# LPC18xx register map
File version: 18
Registers are 32-bit, read-write, reset 0x0 unless marked. A register's access mark holds for its fields unless they carry their own. Offsets are from the block's base; [hi:lo] are bit positions.

## ETHERNET — Product name title=UM10430 Chapter title=LPC18xx Ethernet Modification date=1/20/2011 Major revision=0 Minor revision=7
Base 0x40010000
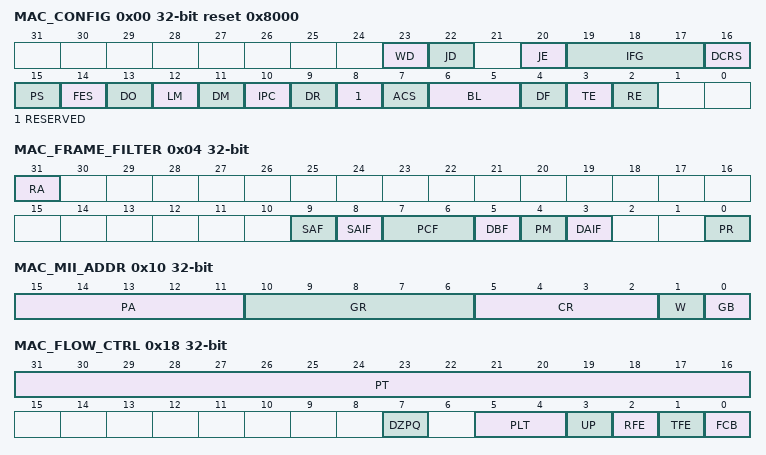
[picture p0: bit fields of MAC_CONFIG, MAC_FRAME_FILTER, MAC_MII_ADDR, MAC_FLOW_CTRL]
0x00 MAC_CONFIG reset 0x8000 — MAC configuration register
  [23] WD — Watchdog Disable When this bit is set, the MAC disables the watchdog timer on the receiver, and can receive frames of up to 16,384 bytes. When this bit is reset, the MAC allows no more than 2,048 bytes (10,240 if JE is set high) of the frame being received and cuts off any bytes received after that.
  [22] JD — Jabber Disable When this bit is set, the MAC disables the jabber timer on the transmitter, and can transfer frames of up to 16,384 bytes. When this bit is reset, the MAC cuts off the transmitter if the application sends out more than 2,048 bytes of data (10,240 if JE is set high) during transmission.
  [20] JE — Jumbo Frame Enable When this bit is set, MAC allows Jumbo frames of 9,018 bytes (9,022 bytes for VLAN tagged frames) without reporting a giant frame error in the receive frame status.
  [19:17] IFG — Inter-frame gap These bits control the minimum IFG between frames during transmission. 000 = 96 bit times 001 = 88 bit times 010 = 80 bit times ... 000 = 40 bit times Note that in Half-Duplex mode, the minimum IFG can be configured for 64 bit times (IFG = 100) only. Lower values are not considered
  [16] DCRS — Disable carrier sense during transmission When set high, this bit makes the MAC transmitter ignore the (G)MII CRS signal during frame transmission in Half-Duplex mode. This request results in no errors generated due to Loss of Carrier or No Carrier during such transmission. When this bit is low, the MAC transmitter generates such errors due to Carrier Sense and will even abort the transmissions.
  [15] PS — Port select 1 = MII (100 Mbp) - this is the only allowed value.
  [14] FES — Speed Indicates the speed in Fast Ethernet (MII) mode: 0 = 10 Mbps 1 = 100 Mbps .
  [13] DO — Disable Receive Own When this bit is set, the MAC disables the reception of frames in Half-Duplex mode. When this bit is reset, the MAC receives all packets that are given by the PHY while transmitting. This bit is not applicable if the MAC is operating in Full-Duplex mode.
  [12] LM — Loopback Mode When this bit is set, the MAC operates in loopback mode at MII. The (G)MII Receive clock input is required for the loopback to work properly, as the Transmit clock is not looped-back internally.
  [11] DM — Duplex Mode When this bit is set, the MAC operates in a Full-Duplex mode where it can transmit and receive simultaneously.
  [10] IPC — Checksum Offload When this bit is set, the MAC calculates the 16-bit one's complement of the one's complement sum of all received Ethernet frame payloads. It also checks whether the IPv4 Header checksum (assumed to be bytes 25-26 or 29-30 (VLAN-tagged) of the received Ethernet frame) is correct for the received frame and gives the status in the receive status word. The MAC core also appends the 16-bit checksum calculated for the IP header datagram payload (bytes after the IPv4 header) and appends it to the Ethernet frame transferred to the application (when Type 2 COE is deselected). When this bit is reset, this function is disabled. When Type 2 COE is selected, this bit, when set, enables IPv4 checksum checking for received frame payload's TCP/UDP/ICMP headers. When this bit is reset, the COE function in the receiver is disabled and the corresponding PCE and IP HCE status bits (see ) are always cleared.
  [9] DR — Disable Retry When this bit is set, the MAC will attempt only 1 transmission. When a collision occurs on the MII, the MAC will ignore the current frame transmission and report a Frame Abort with excessive collision error in the transmit frame status. When this bit is reset, the MAC will attempt retries based on the settings of BL. This bit is applicable only to Half-Duplex mode and is reserved (RO with default value) in Full- Duplex-only configuration.
  [8] RESERVED — Link Up/Down Indicates whether the link is up or down during the transmission of configuration in SMII interface: 0 = Link down 1 = Link up
  [7] ACS — Automatic Pad/CRC Stripping When this bit is set, the MAC strips the Pad/FCS field on incoming frames only if the length's field value is less than or equal to 1,500 bytes. All received frames with length field greater than or equal to 1,501 bytes are passed to the application without stripping the Pad/FCS field. When this bit is reset, the MAC will pass all incoming frames to the Host unmodified.
  [6:5] BL — Back-Off Limit The Back-Off limit determines the random integer number (r) of slot time delays (4,096 bit times for 1000 Mbps and 512 bit times for 10/100 Mbps) the MAC waits before rescheduling a transmission attempt during retries after a collision. This bit is applicable only to Half-Duplex mode and is reserved (RO) in Full-Duplex-only configuration. 00: k = min (n, 10) 01: k = min (n, 8) 10: k = min (n, 4) 11: k = min (n, 1) where n = retransmission attempt. The random integer r takes the value in the range between 0 and 2^k.
  [4] DF — Deferral Check When this bit is set, the deferral check function is enabled in the MAC. The MAC will issue a Frame Abort status, along with the excessive deferral error bit set in the transmit frame status when the transmit state machine is deferred for more than 24,288 bit times in 10/100-Mbps mode. If the Core is configured for 1000 Mbps operation, or if the Jumbo frame mode is enabled in 10/100-Mbps mode, the threshold for deferral is 155,680 bits times. Deferral begins when the transmitter is ready to transmit, but is prevented because of an active CRS (carrier sense) signal on the MII. Defer time is not cumulative. If the transmitter defers for 10,000 bit times, then transmits, collides, backs off, and then has to defer again after completion of back-off, the deferral timer resets to 0 and restarts. When this bit is reset, the deferral check function is disabled and the MAC defers until the CRS signal goes inactive. This bit is applicable only in Half-Duplex mode and is reserved (RO) in Full-Duplex-only configuration.
  [3] TE — Transmitter Enable When this bit is set, the transmit state machine of the MAC is enabled for transmission on the MII. When this bit is reset, the MAC transmit state machine is disabled after the completion of the transmission of the current frame, and will not transmit any further frames.
  [2] RE — Receiver enable When this bit is set, the receiver state machine of the MAC is enabled for receiving frames from the MII. When this bit is reset, the MAC receive state machine is disabled after the completion of the reception of the current frame, and will not receive any further frames from the MII.
0x04 MAC_FRAME_FILTER
  [31] RA — Receive all When this bit is set, the MAC Receiver module passes to the Application all frames received irrespective of whether they pass the address filter. The result of the SA/DA filtering is updated (pass or fail) in the corresponding bits in the Receive Status Word. When this bit is reset, the Receiver module passes to the Application only those frames that pass the SA/DA address filter.
  [9] SAF — Source Address Filter Enable The MAC core compares the SA field of the received frames with the values programmed in the enabled SA registers. If the comparison matches, then the SAMatch bit of RxStatus Word is set high. When this bit is set high and the SA filter fails, the MAC drops the frame. When this bit is reset, then the MAC Core forwards the received frame to the application and with the updated SA Match bit of the RxStatus depending on the SA address comparison.
  [8] SAIF — SA Inverse Filtering When this bit is set, the Address Check block operates in inverse filtering mode for the SA address comparison. The frames whose SA matches the SA registers will be marked as failing the SA Address filter. When this bit is reset, frames whose SA does not match the SA registers will be marked as failing the SA Address filter.
  [7:6] PCF — Pass Control Frames These bits control the forwarding of all control frames (including unicast and multicast PAUSE frames). Note that the processing of PAUSE control frames depends only on RFE of Flow Control Register[2]. 00 = MAC filters all control frames from reaching the application. 01 = MAC forwards all control frames except PAUSE control frames to application even if they fail the Address filter. 10 = MAC forwards all control frames to application even if they fail the Address Filter. 11 = MAC forwards control frames that pass the Address Filter.
  [5] DBF — Disable Broadcast Frames When this bit is set, the AFM module filters all incoming broadcast frames. When this bit is reset, the AFM module passes all received broadcast frames.
  [4] PM — Pass All Multicast When set, this bit indicates that all received frames with a multicast destination address (first bit in the destination address field is '1') are passed. When reset, filtering of multicast frame depends on HMC bit.
  [3] DAIF — DA Inverse Filtering When this bit is set, the Address Check block operates in inverse filtering mode for the DA address comparison for both unicast and multicast frames. When reset, normal filtering of frames is performed.
  [0] PR — Promiscuous Mode When this bit is set, the Address Filter module passes all incoming frames regardless of its destination or source address. The SA/DA Filter Fails status bits of the Receive Status Word will always be cleared when PR is set.
0x08 MAC_HASHTABLE_HIGH — Hash table high register
  [31:0] HTH — Hash table high This field contains the upper 32 bits of Hash table.
0x0C MAC_HASHTABLE_LOW — Hash table low register
  [31:0] HTL — Hash table low This field contains the upper 32 bits of Hash table.
0x10 MAC_MII_ADDR — MII address register
  [15:11] PA — Physical layer address This field tells which of the 32 possible PHY devices are being accessed.
  [10:6] GR — MII register These bits select the desired MII register in the selected PHY device.
  [5:2] CR — CSR clock range The CSR Clock Range selection determines the frequency of the MDC clock . The suggested range of clk_csr_i frequency applicable for each value below (when Bit[5] = 0) ensures that the MDC clock is approximately between the frequency range 1.0 MHz - 2.5 MHz. When bit 5 is set, you can achieve MDC clock of frequency higher than the IEEE 802.3 specified frequency limit of 2.5 MHz and program a clock divider of lower value. For example, when clk_csr_i is of frequency 100 Mhz and you program these bits as 1010, then the resultant MDC clock will be of 12.5 Mhz which is outside the limit of IEEE 802.3 specified range. Please program the values given below only if the interfacing chips supports faster MDC clocks. See Table 320 for bit values.
  [1] W — MII write When set, this bit tells the PHY that this will be a Write operation using the MII Data register. If this bit is not set, this will be a Read operation, placing the data in the MII Data register.
  [0] GB — MII busy This bit should read a logic 0 before writing to this register and the MAC_MII_DATA register. This bit must also be set to 0 during a Write to this register. During a PHY register access, this bit will be set to 1 by the Application to indicate that a Read or Write access is in progress. The MAC_MII_DATA register should be kept valid until this bit is cleared by the MAC during a PHY Write operation. The MAC_MII_DATA register is invalid until this bit is cleared by the MAC during a PHY Read operation. This register should not be written to until this bit is cleared.
0x14 MAC_MII_DATA — MII data register
  [15:0] GD — MII data This contains the 16-bit data value read from the PHY after a Management Read operation or the 16-bit data value to be written to the PHY before a Management Write operation.
0x18 MAC_FLOW_CTRL — Flow control register
  [31:16] PT — Pause time This field holds the value to be used in the Pause Time field in the transmit control frame. If the Pause Time bits is configured to be double-synchronized to the (G)MII clock domain, then consecutive writes to this register should be performed only after at least 4 clock cycles in the destination clock domain.
  [7] DZPQ — Disable Zero-Quanta Pause When set, this bit disables the automatic generation of Zero-Quanta Pause Control frames on the deassertion of the flow-control signal from the FIFO layer . When this bit is reset, normal operation with automatic Zero-Quanta Pause Control frame generation is enabled.
  [5:4] PLT — Pause Low Threshold This field configures the threshold of the PAUSE timer at which the input flow control is checked for automatic retransmission of PAUSE Frame. The threshold values should be always less than the Pause Time configured in Bits[31:16]. For example, if PT = Ox100 (256 slot-times), and PLT = 01, then a second PAUSE frame is automatically transmitted if the flow control signal is asserted at 228 (256 - 28) slot-times after the first PAUSE frame is transmitted.
  [3] UP — Unicast Pause Frame Detect When this bit is set, the MAC will detect the Pause frames with the station's unicast address specified in MAC Address0 High Register and MAC Address0 Low Register, in addition to the detecting Pause frames with the unique multicast address. When this bit is reset, the MAC will detect only a Pause frame with the unique multicast address specified in the 802.3x standard.
  [2] RFE — Receive Flow Control Enable When this bit is set, the MAC will decode the received Pause frame and disable its transmitter for a specified (Pause Time) time. When this bit is reset, the decode function of the Pause frame is disabled.
  [1] TFE — Transmit Flow Control Enable In Full-Duplex mode, when this bit is set, the MAC enables the flow control operation to transmit Pause frames. When this bit is reset, the flow control operation in the MAC is disabled, and the MAC will not transmit any Pause frames. In Half-Duplex mode, when this bit is set, the MAC enables the back-pressure operation. When this bit is reset, the backpressure feature is disabled.
  [0] FCB — Flow Control Busy/Backpressure Activate This bit initiates a Pause Control frame in Full-Duplex mode. In Full-Duplex mode, this bit should be read as 0 before writing to the Flow Control register. To initiate a Pause control frame, the Application must set this bit to 1. During a transfer of the Control Frame, this bit will continue to be set to signify that a frame transmission is in progress. After the completion of Pause control frame transmission, the MAC will reset this bit to 0. The Flow Control register should not be written to until this bit is cleared. In Half-Duplex mode, when this bit is set (and TFE is set), then backpressure is asserted by the MAC Core. During backpressure, when the MAC receives a new frame, the transmitter starts sending a JAM pattern resulting in a collision. This control register bit is logically OR'ed with the mti_flowctrl_i input signal for the backpressure function. When the MAC is configured to Full- Duplex mode, the BPA is automatically disabled.
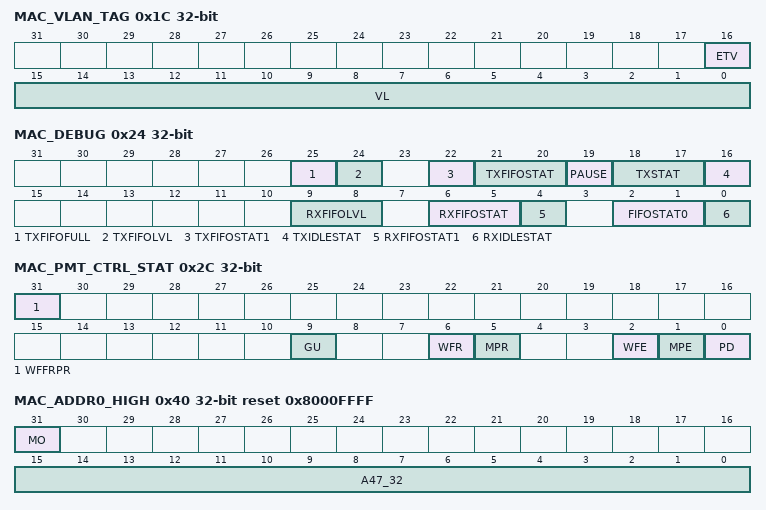
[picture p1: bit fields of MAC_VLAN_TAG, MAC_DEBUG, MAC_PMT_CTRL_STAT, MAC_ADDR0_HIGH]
0x1C MAC_VLAN_TAG — VLAN tag register
  [16] ETV — Enable 12-Bit VLAN Tag Comparison When this bit is set, a 12-bit VLAN identifier, rather than the complete 16-bit VLAN tag, is used for comparison and filtering. Bits[11:0] of the VLAN tag are compared with the corresponding field in the received VLAN-tagged frame. When this bit is reset, all 16 bits of the received VLAN frame's fifteenth and sixteenth bytes are used for comparison.
  [15:0] VL — VLAN Tag Identifier for Receive Frames This contains the 802.1Q VLAN tag to identify VLAN frames, and is compared to the fifteenth and sixteenth bytes of the frames being received for VLAN frames. Bits[15:13] are the User Priority, Bit[12] is the Canonical Format Indicator (CFI) and bits[11:0] are the VLAN tag's VLAN Identifier (VID) field. When the ETV bit is set, only the VID (Bits[11:0]) is used for comparison. If VL (VL[11:0] if ETV is set) is all zeros, the MAC does not check the fifteenth and sixteenth bytes for VLAN tag comparison, and declares all frames with a Type field value of 0x8100 to be VLAN frames.
0x24 MAC_DEBUG — Debug register
  [25] TXFIFOFULL — When high, it indicates that the MTL TxStatus FIFO is full and hence the MTL will not be accepting any more frames for transmission.
  [24] TXFIFOLVL — When high, it indicates that the MTL TxFIFO is not empty and has some data left for transmission.
  [22] TXFIFOSTAT1 — When high, it indicates that the MTL TxFIFO Write Controller is active and transferring data to the TxFIFO.
  [21:20] TXFIFOSTAT — State of the TxFIFO read Controller 00 = idle state 01 = READ state (transferring data to MAC transmitter) 10 = Waiting for TxStatus from MAC transmitter 11 = Writing the received TxStatus or flushing the TxFIFO
  [19] PAUSE — When high, it indicates that the MAC transmitter is in PAUSE condition (in full-duplex only) and hence will not schedule any frame for transmission.
  [18:17] TXSTAT — State of the MAC Transmit Frame Controller module: 00 = idle 01 = Waiting for Status of previous frame or IFG/backoff period to be over 10 = Generating and transmitting a PAUSE control frame (in full duplex mode) 11 = Transferring input frame for transmission
  [16] TXIDLESTAT — When high, it indicates that the MAC MII transmit protocol engine is actively transmitting data and not in IDLE state.
  [9:8] RXFIFOLVL — Status of the RxFIFO Fill-level 00 = RxFIFO Empty 01 = RxFIFO fill-level below flow-control de-activate threshold 10 = RxFIFO fill-level above flow-control activate threshold 11 = RxFIFO Full
  [6:5] RXFIFOSTAT — State of the RxFIFO read Controller: 00 = idle state 01 = reading frame data 10 = reading frame status (or time stamp) 11 = flushing the frame data and status
  [4] RXFIFOSTAT1 — When high, it indicates that the MTL RxFIFO Write Controller is active and transferring a received frame to the FIFO.
  [2:1] FIFOSTAT0 — When high, it indicates the active state of the small FIFO Read and Write controllers respectively of the MAC receive Frame Controller module.
  [0] RXIDLESTAT — When high, it indicates that the MAC MII receive protocol engine is actively receiving data and not in IDLE state.
0x28 MAC_RWAKE_FRFLT — Remote wake-up frame filter
  [31:0] ADDR — WKUPFMFILTER address
0x2C MAC_PMT_CTRL_STAT — PMT control and status
  [31] WFFRPR — Wake-up Frame Filter Register Pointer Reset When set, resets the Remote Wake-up Frame Filter register pointer to 000. It is automatically cleared after 1 clock cycle.
  [9] GU — Global Unicast When set, enables any unicast packet filtered by the MAC (DAF) address recognition to be a wake-up frame.
  [6] WFR — Wake-up Frame Received When set, this bit indicates the power management event was generated due to reception of a wake-up frame. This bit is cleared by a Read into this register.
  [5] MPR — Magic Packet Received When set, this bit indicates the power management event was generated by the reception of a Magic Packet. This bit is cleared by a Read into this register.
  [2] WFE — Wake-up frame enable When set, enables generation of a power management event due to wake-up frame reception.
  [1] MPE — Magic packet enable When set, enables generation of a power management event due to Magic Packet reception.
  [0] PD — Power-down When set, all received frames will be dropped. This bit is cleared automatically when a magic packet or Wake-Up frame is received, and Power-Down mode is disabled. Frames received after this bit is cleared are forwarded to the application.This bit must only be set when either the Magic Packet Enable or Wake- Up Frame Enable bit is set high.
0x38 MAC_INTR — Interrupt status register
0x3C MAC_INTR_MASK — Interrupt mask register
  [3] PMTMSK — PMT Interrupt Mask This bit when set, will disable the assertion of the interrupt signal due to the setting of PMT Interrupt Status bit in Table 327.
0x40 MAC_ADDR0_HIGH reset 0x8000FFFF — MAC address 0 high register
  [31] MO — Always 1
  [15:0] A47_32 — MAC Address0 [47:32] This field contains the upper 16 bits (47:32) of the 6-byte first MAC address. This is used by the MAC for filtering for received frames and for inserting the MAC address in the Transmit Flow Control (PAUSE) Frames.
0x44 MAC_ADDR0_LOW reset 0xFFFFFFFF — MAC address 0 low register
  [31:0] A31_0 — MAC Address0 [31:0] This field contains the lower 32 bits of the 6-byte first MAC address. This is used by the MAC for filtering for received frames and for inserting the MAC address in the Transmit Flow Control (PAUSE) Frames.
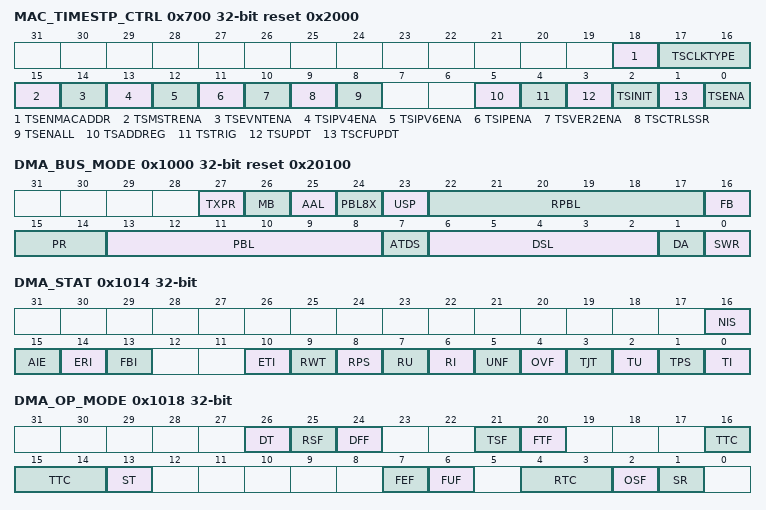
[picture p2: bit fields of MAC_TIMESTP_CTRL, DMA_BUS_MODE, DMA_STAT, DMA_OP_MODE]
0x700 MAC_TIMESTP_CTRL reset 0x2000 — Time stamp control register
  [18] TSENMACADDR — Enable MAC address for PTP frame filtering When set, uses the DA MAC address (that matches any MAC Address register except the default MAC address 0) to filter the PTP frames when PTP is sent directly over Ethernet.
  [17:16] TSCLKTYPE — Select the type of clock node The following are the options to select the type of clock node: 00 = ordinary clock 01 = boundary clock 10 = end-to-end transparent clock 11 = peer-to-peer transparent clock
  [15] TSMSTRENA — Enable Snapshot for Messages Relevant to Master When set, the snapshot is taken for messages relevant to master node only else snapshot is taken for messages relevant to slave node. This is valid only for ordinary clock and boundary clock node.
  [14] TSEVNTENA — Enable Time Stamp Snapshot for Event Messages When set, the time stamp snapshot is taken for event messages only . When reset snapshot is taken for all other messages except Announce, Management and Signaling.
  [13] TSIPV4ENA — Enable Time Stamp Snapshot for IPv4 frames When set, the time stamp snapshot is taken for IPv4 frames.
  [12] TSIPV6ENA — Enable Time Stamp Snapshot for IPv6 frames When set, the time stamp snapshot is taken for IPv6 frames.
  [11] TSIPENA — Enable Time Stamp Snapshot for PTP over Ethernet frames When set, the time stamp snapshot is taken for frames which have PTP messages in Ethernet frames (PTP over Ethernet) also. By default snapshots are taken for UDP-IP-Ethernet PTP packets.
  [10] TSVER2ENA — Enable PTP packet snooping for version 2 format When set, the PTP packets are snooped using the 1588 version 2 format else snooped using the version 1 format.
  [9] TSCTRLSSR — Time Stamp Digital or Binary rollover control When set, the Time Stamp Low register rolls over after 0x3B9A_C9FF value (i.e., 1 nanosecond accuracy) and increments the Time Stamp (High) seconds. When reset, the rollover value of sub-second register is 0x7FFF_FFFF. The sub-second increment has to be programmed correctly depending on the PTP reference clock frequency and this bit value.
  [8] TSENALL — Enable Time Stamp for All Frames When set, the time stamp snapshot is enabled for all frames received by the core.
  [5] TSADDREG — Addend Reg Update When set, the contents of the Time Stamp Addend register is updated in the PTP block for fine correction. This is cleared when the update is completed. This register bit should be zero before setting it. This is a reserved bit when only coarse correction option is selected.
  [4] TSTRIG — Time Stamp Interrupt Trigger Enable When set, the Time Stamp interrupt is generated when the System Time becomes greater than the value written in Target Time register. This bit is reset after the generation of Time Stamp Trigger Interrupt.
  [3] TSUPDT — Time Stamp Update When set, the system time is updated (added/subtracted) with the value specified in the Time Stamp High Update and Time Stamp Low Update registers. This register bit should be read zero before updating it. This bit is reset once the update is completed in hardware.
  [2] TSINIT — Time Stamp Initialize When set, the system time is initialized (over-written) with the value specified in the Time Stamp High Update and Time Stamp Low Update registers. This register bit should be read zero before updating it. This bit is reset once the initialize is complete.
  [1] TSCFUPDT — Time Stamp Fine or Coarse Update When set, indicates that the system times update to be done using fine update method. When reset it indicates the system time stamp update to be done using Coarse method. This bit is reserved if the fine correction option is not enabled.
  [0] TSENA — Time Stamp Enable When this bit, is set the timestamping is enabled for transmit and receive frames. When disabled timestamp is not added for transmit and receive frames and the TimeStamp Generator is also suspended. User has to always initialize the TimeStamp (system time) after enabling this mode.
0x1000 DMA_BUS_MODE reset 0x20100 — Bus Mode Register
  [27] TXPR — When set, this bit indicates that the transmit DMA has higher priority than the receive DMA during arbitration for the system-side bus.
  [26] MB — Mixed burst When this bit is set high and FB bit is low, the AHB master interface will start all bursts of length more than 16 with INCR (undefined burst) whereas it will revert to fixed burst transfers (INCRx and SINGLE) for burst-length of 16 and below.
  [25] AAL — Address-aligned beats When this bit is set high and the FB bit equals 1, the AHB interface generates all bursts aligned to the start address LS bits. If the FB bit equals 0, the first burst (accessing the data buffer's start address) is not aligned, but subsequent bursts are aligned to the address.
  [24] PBL8X — 8 x PBL mode When set high, this bit multiplies the PBL value programmed (bits [22:17] and bits [13:8]) eight times. Thus the DMA will transfer data in to a maximum of 8, 16, 32, 64, 128, and 256 beats depending on the PBL value. This bit function is not backward compatible. Before version 3.50a, this bit was 4xPBL.
  [23] USP — Use separate PBL When set high, it configures the RxDMA to use the value configured in bits [22:17] as PBL while the PBL value in bits [13:8] is applicable to TxDMA operations only. When reset to low, the PBL value in bits [13:8] is applicable for both DMA engines.
  [22:17] RPBL — RxDMA PBL These bits indicate the maximum number of beats to be transferred in one RxDMA transaction. This will be the maximum value that is used in a single block Read/Write. The RxDMA will always attempt to burst as specified in RPBL each time it starts a Burst transfer on the host bus. RPBL can be programmed with permissible values of 1, 2, 4, 8, 16, and 32. Any other value will result in undefined behavior. These bits are valid and applicable only when USP is set high.
  [16] FB — Fixed burst This bit controls whether the AHB Master interface performs fixed burst transfers or not. When set, the AHB will use only SINGLE, INCR4, INCR8 or INCR16 during start of normal burst transfers. When reset, the AHB will use SINGLE and INCR burst transfer operations.
  [15:14] PR — Rx-to-Tx priority ratio RxDMA requests given priority over TxDMA requests in the following ratio. This is valid only when the DA bit is reset. 00 = 1-to-1 01 = 2-to-1 10 = 3-to-1 11 = 4-to-1
  [13:8] PBL — Programmable burst length These bits indicate the maximum number of beats to be transferred in one DMA transaction. This will be the maximum value that is used in a single block Read/Write. The DMA will always attempt to burst as specified in PBL each time it starts a Burst transfer on the host bus. PBL can be programmed with permissible values of 1, 2, 4, 8, 16, and 32. Any other value will result in undefined behavior. When USP is set high, this PBL value is applicable for TxDMA transactions only. The PBL values have the following limitations. The maximum number of beats (PBL) possible is limited by the size of the Tx FIFO and Rx FIFO in the MTL layer and the data bus width on the DMA. The FIFO has a constraint that the maximum beat supported is half the depth of the FIFO, except when specified (as given below). For different data bus widths and FIFO sizes, the valid PBL range (including x8 mode) is provided in the following table. If the PBL is common for both transmit and receive DMA, the minimum Rx FIFO and Tx FIFO depths must be considered. Do not program out-of-range PBL values, because the system may not behave properly.
  [7] ATDS — Alternate (Enhanced) descriptor size When set, the alternate (enhanced) descriptor (see Section 20.9) size is increased to 32 bytes (8 DWORDS). This is required when the Advanced Time-Stamp feature or Full IPC Offload Engine is enabled in the receiver. When reset, the descriptor size reverts back to 4 DWORDs (16 bytes). This bit is present only when Alternate Descriptor feature is selected and either Advanced Time Stamp or IPC Full Checksum Offload (type 2) feature is selected during configuration. Otherwise, this bit is reserved and read-only.
  [6:2] DSL — Descriptor skip length This bit specifies the number of Word/Dword/Lword (depending on 32/64/128-bit bus) to skip between two unchained descriptors. The address skipping starts from the end of current descriptor to the start of next descriptor. When DSL value equals zero, then the descriptor table is taken as contiguous by the DMA, in Ring mode.
  [1] DA — DMA arbitration scheme 0 = Round-robin with Rx:Tx priority given in bits [15:14] 1 = Rx has priority over Tx
  [0] SWR — Software reset When this bit is set, the MAC DMA Controller resets all MAC Subsystem internal registers and logic. It is cleared automatically after the reset operation has completed in all of the core clock domains. Read a 0 value in this bit before re-programming any register of the core. The reset operation is completed only when all the resets in all the active clock domains are de-asserted. Hence it is essential that all the PHY inputs clocks (applicable for the selected PHY interface) are present for software reset completion.
0x1004 DMA_TRANS_POLL_DEMAND — Transmit poll demand register
  [31:0] TPD — Transmit poll demand When these bits are written with any value, the DMA reads the current descriptor pointed to by the Current Host Transmit Descriptor register (Section 20.6.27). If that descriptor is not available (owned by Host), transmission returns to the Suspend state and bit 2 in the DMA_STAT Register is asserted. If the descriptor is available, transmission resumes.
0x1008 DMA_REC_POLL_DEMAND — Receive poll demand register
  [31:0] RPD — Receive poll demand When these bits are written with any value, the DMA reads the current descriptor pointed to by the Current Host Receive Descriptor register (Section 20.6.28). If that descriptor is not available (owned by Host), reception returns to the Suspended state and bit 7 in the DMA_STAT Register is not asserted. If the descriptor is available, the Receive DMA returns to active state.
0x100C DMA_REC_DES_ADDR — Receive descriptor list address register
  [31:0] SRL — Start of receive list This field contains the base address of the First Descriptor in the Receive Descriptor list. The LSB bits [1/2/3:0] for 32/64/128-bit bus width) will be ignored and taken as all-zero by the DMA internally. Hence these LSB bits are Read Only.
0x1010 DMA_TRANS_DES_ADDR — Transmit descriptor list address register
  [31:0] SRL — Start of transmit list This field contains the base address of the First Descriptor in the Transmit Descriptor list. The LSB bits [1/2/3:0] for 32/64/128-bit bus width) will be ignored and taken as all-zero by the DMA internally. Hence these LSB bits are Read Only.
0x1014 DMA_STAT — Status register
  [16] NIS — Normal interrupt summary Normal Interrupt Summary bit value is the logical OR of the following when the corresponding interrupt bits are enabled in the DMA_INT_EN register: DMA_STAT register, bit 0: Transmit interrupt DMA_STAT register, bit 2: Transmit buffer unavailable DMA_STAT register, bit 6: Receive interrupt DMA_STAT register, bit 14: Early receive interrupt Only unmasked bits affect the Normal Interrupt Summary bit. This is a sticky bit and must be cleared (by writing a 1 to this bit) each time a corresponding bit that causes NIS to be set is cleared.
  [15] AIE — Abnormal interrupt summary Abnormal Interrupt Summary bit value is the logical OR of the following when the corresponding interrupt bits are enabled in the DMA_INT_EN register: DMA_STAT register, bit 1: Transmit process stopped DMA_STAT register, bit 3: Transmit jabber timeout DMA_STAT register, bit 4: Receive overflow DMA_STAT register, bit 5: Transmit underflow DMA_STAT register, bit 7: Receiver buffer unavailable DMA_STAT register, bit 8: Receive process stopped DMA_STAT register, bit 9: Receive watchdog timeout DMA_STAT register, bit 10: Early transmit interrupt DMA_STAT register, bit 13: Fatal bus error Only unmasked bits affect the Abnormal Interrupt Summary bit. This is a sticky bit and must be cleared each time a corresponding bit that causes AIS to be set is cleared.
  [14] ERI — Early receive interrupt This bit indicates that the DMA had filled the first data buffer of the packet. Receive Interrupt bit 6 in this register automatically clears this bit.
  [13] FBI — Fatal bus error interrupt This bit indicates that a bus error occurred, as detailed in bits [25:23]. When this bit is set, the corresponding DMA engine disables all its bus accesses.
  [10] ETI — Early transmit interrupt This bit indicates that the frame to be transmitted was fully transferred to the MTL Transmit FIFO.
  [9] RWT — Receive watchdog timeout This bit is asserted when a frame with a length greater than 2,048 bytes is received (10,240 when Jumbo Frame mode is enabled).
  [8] RPS — Received process stopped This bit is asserted when the Receive Process enters the Stopped state.
  [7] RU — Receive buffer unavailable This bit indicates that the Next Descriptor in the Receive List is owned by the host and cannot be acquired by the DMA. Receive Process is suspended. To resume processing Receive descriptors, the host should change the ownership of the descriptor and issue a Receive Poll Demand command. If no Receive Poll Demand is issued, Receive Process resumes when the next recognized incoming frame is received. This bit is set only when the previous Receive Descriptor was owned by the DMA.
  [6] RI — Receive interrupt This bit indicates the completion of frame reception. Specific frame status information has been posted in the descriptor. Reception remains in the Running state.
  [5] UNF — Transmit underflow This bit indicates that the Transmit Buffer had an Underflow during frame transmission. Transmission is suspended and an Underflow Error TDES0[1] is set.
  [4] OVF — Receive overflow This bit indicates that the Receive Buffer had an Overflow during frame reception. If the partial frame is transferred to application, the overflow status is set in RDES0[11].
  [3] TJT — Transmit jabber timeout This bit indicates that the Transmit Jabber Timer expired, meaning that the transmitter had been excessively active. The transmission process is aborted and placed in the Stopped state. This causes the Transmit Jabber Timeout TDES0[14] flag to assert.
  [2] TU — Transmit buffer unavailable This bit indicates that the Next Descriptor in the Transmit List is owned by the host and cannot be acquired by the DMA. Transmission is suspended. Bits[22:20] explain the Transmit Process state transitions. To resume processing transmit descriptors, the host should change the ownership of the bit of the descriptor and then issue a Transmit Poll Demand command.
  [1] TPS — Transmit process stopped This bit is set when the transmission is stopped.
  [0] TI — Transmit interrupt This bit indicates that frame transmission is finished and TDES1[31] is set in the First Descriptor.
0x1018 DMA_OP_MODE — Operation mode register
  [26] DT — Disable Dropping of TCP/IP Checksum Error Frames When this bit is set, the core does not drop frames that only have errors detected by the Receive Checksum Offload engine. Such frames do not have any errors (including FCS error) in the Ethernet frame received by the MAC but have errors in the encapsulated payload only. When this bit is reset, all error frames are dropped if the FEF bit is reset.
  [25] RSF — Receive store and forward When this bit is set, the MTL only reads a frame from the Rx FIFO after the complete frame has been written to it, ignoring RTC bits. When this bit is reset, the Rx FIFO operates in Cut-Through mode, subject to the threshold specified by the RTC bits.
  [24] DFF — Disable flushing of received frames When this bit is set, the RxDMA does not flush any frames due to the unavailability of receive descriptors/buffers as it does normally when this bit is reset. (See ).
  [21] TSF — Transmit store and forward When this bit is set, transmission starts when a full frame resides in the MTL Transmit FIFO. When this bit is set, the TTC values specified in this register (bits [16:14]) are ignored. This bit should be changed only when transmission is stopped.
  [20] FTF — Flush transmit FIFO When this bit is set, the transmit FIFO controller logic is reset to its default values and thus all data in the Tx FIFO is lost/flushed. This bit is cleared internally when the flushing operation is completed fully. The Operation Mode register should not be written to until this bit is cleared. The data which is already accepted by the MAC transmitter will not be flushed. It will be scheduled for transmission and will result in underflow and runt frame transmission. The flush operation completes only after emptying the TxFIFO of its contents and all the pending Transmit Status of the transmitted frames are accepted by the host. In order to complete this flush operation, the PHY transmit clock is required to be active.
  [16:14] TTC — Transmit threshold control These three bits control the threshold level of the MTL Transmit FIFO. Transmission starts when the frame size within the MTL Transmit FIFO is larger than the threshold. In addition, full frames with a length less than the threshold are also transmitted. These bits are used only when the TSF bit (Bit 21) is reset. 000 = 64 001 = 128 010 = 192 011 = 256 100 = 40 101 = 32 110 = 24 111 = 16
  [13] ST — Start/Stop Transmission Command When this bit is set, transmission is placed in the Running state, and the DMA checks the Transmit List at the current position for a frame to be transmitted. Descriptor acquisition is attempted either from the current position in the list, which is the Transmit List Base Address set by the DMA_TRANS_DES_ADDR register or from the position retained when transmission was stopped previously. If the current descriptor is not owned by the DMA, transmission enters the Suspended state and Transmit Buffer Unavailable (DMA_STAT register, bit 2) is set. The Start Transmission command is effective only when transmission is stopped. If the command is issued before setting the DMA_TRANS_DES_ADDR register, then the DMA behavior is unpredictable. When this bit is reset, the transmission process is placed in the Stopped state after completing the transmission of the current frame. The Next Descriptor position in the Transmit List is saved, and becomes the current position when transmission is restarted. The stop transmission command is effective only the transmission of the current frame is complete or when the transmission is in the Suspended state.
  [7] FEF — Forward error frames When this bit is reset, the Rx FIFO drops frames with error status (CRC error, collision error, GMII_ER, giant frame, watchdog timeout, overflow). However, if the frame's start byte (write) pointer is already transferred to the read controller side (in Threshold mode), then the frames are not dropped. . When FEF is set, all frames except runt error frames are forwarded to the DMA. But when RxFIFO overflows when a partial frame is written, then such frames are dropped even when FEF is set.
  [6] FUF — Forward undersized good frames When set, the Rx FIFO will forward Undersized frames (frames with no Error and length less than 64 bytes) including pad-bytes and CRC). When reset, the Rx FIFO will drop all frames of less than 64 bytes, unless it is already transferred due to lower value of Receive Threshold (e.g., RTC = 01).
  [4:3] RTC — Receive threshold control These two bits control the threshold level of the MTL Receive FIFO. Transfer (request) to DMA starts when the frame size within the MTL Receive FIFO is larger than the threshold. In addition, full frames with a length less than the threshold are transferred automatically. Note that value of 11 is not applicable if the configured Receive FIFO size is 128 bytes. These bits are valid only when the RSF bit is zero, and are ignored when the RSF bit is set to 1. 00 = 64 01 = 32 10 = 96 11 = 128
  [2] OSF — Operate on second frame When this bit is set, this bit instructs the DMA to process a second frame of Transmit data even before status for first frame is obtained.
  [1] SR — Start/stop receive When this bit is set, the Receive process is placed in the Running state. The DMA attempts to acquire the descriptor from the Receive list and processes incoming frames. Descriptor acquisition is attempted from the current position in the list, which is the address set by the DMA_REC_DES_ADDR register or the position retained when the Receive process was previously stopped. If no descriptor is owned by the DMA, reception is suspended and Receive Buffer Unavailable bit (bit 7 in DMA_STAT register) is set. The Start Receive command is effective only when reception has stopped. If the command was issued before setting the DMA_REC_DES_ADDR, DMA behavior is unpredictable.
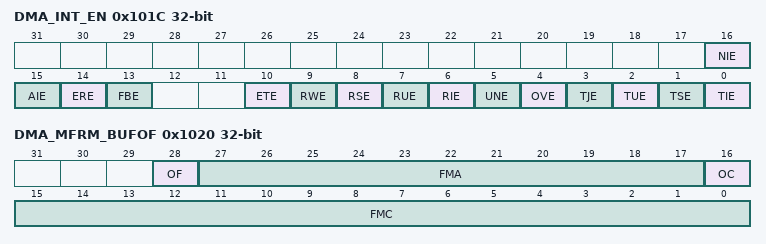
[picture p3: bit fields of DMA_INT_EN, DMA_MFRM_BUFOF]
0x101C DMA_INT_EN — Interrupt enable register
  [16] NIE — Normal interrupt summary enable When this bit is set, a normal interrupt is enabled. When this bit is reset, a normal interrupt is disabled. This bit enables the following bits: DMA_STAT register, bit 0: Transmit interrupt DMA_STAT register, bit 2: Transmit buffer unavailable DMA_STAT register, bit 6: Receive interrupt DMA_STAT register, bit 14: Early receive interrupt
  [15] AIE — Abnormal interrupt summary enable When this bit is set, an Abnormal Interrupt is enabled. When this bit is reset, an Abnormal Interrupt is disabled. This bit enables the following bits DMA_STAT register, bit 1: Transmit process stopped DMA_STAT register, bit 3: Transmit jabber timeout DMA_STAT register, bit 4: Receive overflow DMA_STAT register, bit 5: Transmit underflow DMA_STAT register, bit 7: Receiver buffer unavailable DMA_STAT register, bit 8: Receive process stopped DMA_STAT register, bit 9: Receive watchdog timeout DMA_STAT register, bit 10: Early transmit interrupt DMA_STAT register, bit 13: Fatal bus error
  [14] ERE — Early receive interrupt enable When this bit is set with Normal Interrupt Summary Enable (bit 16 in this register), Early Receive Interrupt is enabled. When this bit is reset, Early Receive Interrupt is disabled.
  [13] FBE — Fatal bus error enable When this bit is set with Abnormal Interrupt Summary Enable (bit 15 in this register), the Fatal Bus Error Interrupt is enabled. When this bit is reset, Fatal Bus Error Enable Interrupt is disabled.
  [10] ETE — Early transmit interrupt enable When this bit is set with an Abnormal Interrupt Summary Enable (bit 15 in this register), Early Transmit Interrupt is enabled. When this bit is reset, Early Transmit Interrupt is disabled.
  [9] RWE — Receive watchdog timeout enable When this bit is set with Abnormal Interrupt Summary Enable (bit 15 in this register), the Receive Watchdog Timeout Interrupt is enabled. When this bit is reset, Receive Watchdog Timeout Interrupt is disabled.
  [8] RSE — Received stopped enable When this bit is set with Abnormal Interrupt Summary Enable (bit 15 in this register), Receive Stopped Interrupt is enabled. When this bit is reset, Receive Stopped Interrupt is disabled.
  [7] RUE — Receive buffer unavailable enable When this bit is set with Abnormal Interrupt Summary Enable (bit 15 in this register), Receive Buffer Unavailable Interrupt is enabled. When this bit is reset, the Receive Buffer Unavailable Interrupt is disabled.
  [6] RIE — Receive interrupt enable When this bit is set with Normal Interrupt Summary Enable (bit 16 in this register), Receive Interrupt is enabled. When this bit is reset, Receive Interrupt is disabled.
  [5] UNE — Underflow interrupt enable When this bit is set with Abnormal Interrupt Summary Enable (bit 15 in this register), Transmit Underflow Interrupt is enabled. When this bit is reset, Underflow Interrupt is disabled.
  [4] OVE — Overflow interrupt enable When this bit is set with Abnormal Interrupt Summary Enable (bit 15 in this register), Receive Overflow Interrupt is enabled. When this bit is reset, Overflow Interrupt is disabled.
  [3] TJE — Transmit jabber timeout enable When this bit is set with Abnormal Interrupt Summary Enable (bit 15 in this register), Transmit Jabber Timeout Interrupt is enabled. When this bit is reset, Transmit Jabber Timeout Interrupt is disabled.
  [2] TUE — Transmit buffer unavailable enable When this bit is set with Normal Interrupt Summary Enable (bit 16 in this register), Transmit Buffer Unavailable Interrupt is enabled. When this bit is reset, Transmit Buffer Unavailable Interrupt is disabled.
  [1] TSE — Transmit stopped enable When this bit is set with Abnormal Interrupt Summary Enable (bit 15 in this register), Transmission Stopped Interrupt is enabled. When this bit is reset, Transmission Stopped Interrupt is disabled.
  [0] TIE — Transmit interrupt enable When this bit is set with Normal Interrupt Summary Enable (bit 16 in this register), Transmit Interrupt is enabled. When this bit is reset, Transmit Interrupt is disabled.
0x1020 DMA_MFRM_BUFOF — Missed frame and buffer overflow register
  [28] OF — Overflow bit for FIFO overflow counter
  [27:17] FMA — Number of frames missed by the application Indicates the number of frames missed by the application. This counter is incremented each time the MTL asserts the sideband signal mtl_rxoverflow_o. The counter is cleared when this register is read with .
  [16] OC — Overflow bit for missed frame counter
  [15:0] FMC — Number of frames missed Indicates the number of frames missed by the controller due to the Host Receive Buffer being unavailable. This counter is incremented each time the DMA discards an incoming frame. The counter is cleared when this register is read with .
0x1024 DMA_REC_INT_WDT — Receive interrupt watchdog timer register
  [7:0] RIWT — RI watchdog timeout Indicates the number of system clock cycles multiplied by 256 for which the watchdog timer is set. The watchdog timer gets triggered with the programmed value after the RxDMA completes the transfer of a frame for which the RI status bit is not set due to the setting in the corresponding descriptor RDES1[31]. When the watch-dog timer runs out, the RI bit is set and the timer is stopped. The watchdog timer is reset when RI bit is set high due to automatic setting of RI as per RDES1[31] of any received frame.
0x1048 DMA_CURHOST_TRANS_DES — Current host transmit descriptor register
  [31:0] HTD — Host Transmit Descriptor Address Pointer Cleared on Reset. Pointer updated by DMA during operation.
0x104C DMA_CURHOST_REC_DES — Current host receive descriptor register
  [31:0] HRD — Host Receive Descriptor Address Pointer Cleared on Reset. Pointer updated by DMA during operation.
0x1050 DMA_CURHOST_TRANS_BUF — Current host transmit buffer address register
  [31:0] HTB — Host Transmit Buffer Address Pointer Cleared on Reset. Pointer updated by DMA during operation.
0x1054 DMA_CURHOST_REC_BUF — Current host receive buffer address register
  [31:0] HRB — Host Receive Buffer Address Pointer Cleared on Reset. Pointer updated by DMA during operation.
